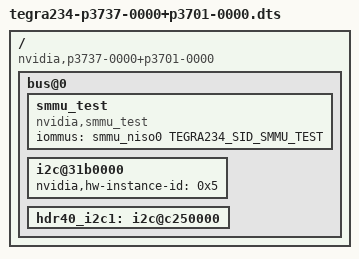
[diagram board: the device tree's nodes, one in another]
// SPDX-License-Identifier: GPL-2.0
// Copyright (c) 2022-2023, NVIDIA CORPORATION & AFFILIATES.  All rights reserved.


/dts-v1/;
/plugin/;

#include "tegra234-overlay.dtsi"
#include "tegra234-soc-thermal.dtsi"
#include "tegra234-soc-thermal-shutdown.dtsi"
#include "tegra234-soc-audio-dai-links.dtsi"
#include "tegra234-soc-camera.dtsi"
#include "tegra234-status-overlay.dtsi"
#include "tegra234-p3737-0000.dtsi"
#include "tegra234-p3701-0000.dtsi"
#include "tegra234-dcb-p3737-0000-p3701-0000.dtsi"

/ {
	compatible = "nvidia,p3737-0000+p3701-0000";

	fragment-t234-p3737-p3701@0 {
		target-path = "/";
		__overlay__ {
			bus@0 {
				smmu_test {
					compatible = "nvidia,smmu_test";
					iommus = <&smmu_niso0 TEGRA234_SID_SMMU_TEST>;
					status = "okay";
				};

				i2c@31b0000 {
					nvidia,hw-instance-id = <0x5>;
				};

				hdr40_i2c1: i2c@c250000 {
				};
			};
		};
	};
};
